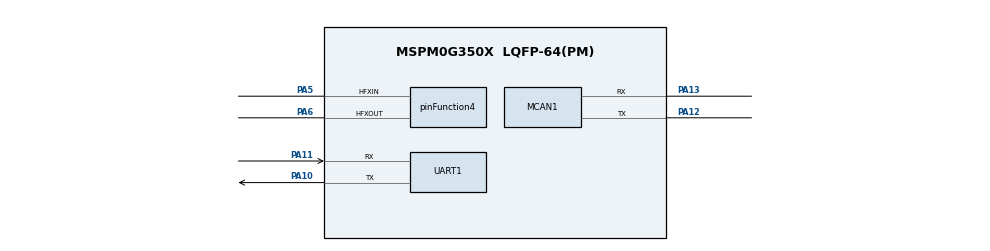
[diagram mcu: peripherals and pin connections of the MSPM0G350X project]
/**
 * @cliArgs --device "MSPM0G350X" --part "Default" --package "LQFP-64(PM)" --product "mspm0_sdk@2.10.00.04"
 * @versions {"tool":"1.27.0+4565"}
 */

/**
 * Import the modules used in this configuration.
 */
const MCAN   = scripting.addModule("/ti/driverlib/MCAN", {}, false);
const MCAN1  = MCAN.addInstance();
const SYSCTL = scripting.addModule("/ti/driverlib/SYSCTL");
const UART   = scripting.addModule("/ti/driverlib/UART", {}, false);
const UART1  = UART.addInstance();

/**
 * Write custom configuration values to the imported modules.
 */
const mux4       = system.clockTree["EXHFMUX"];
mux4.inputSelect = "EXHFMUX_XTAL";

const pinFunction4                        = system.clockTree["HFXT"];
pinFunction4.enable                       = true;
pinFunction4.inputFreq                    = 40;
pinFunction4.HFXTStartup                  = 10;
pinFunction4.HFCLKMonitor                 = true;
pinFunction4.peripheral.$assign           = "SYSCTL";
pinFunction4.peripheral.hfxInPin.$assign  = "PA5";
pinFunction4.peripheral.hfxOutPin.$assign = "PA6";

MCAN1.$name                    = "MCAN0";
MCAN1.enableInterrupt          = true;
MCAN1.autoWkupEnable           = true;
MCAN1.wkupReqEnable            = true;
MCAN1.emulationEnable          = true;
MCAN1.tdcEnable                = true;
MCAN1.additionalCoreConfig     = true;
MCAN1.rrfs                     = true;
MCAN1.rrfe                     = true;
MCAN1.interruptLine            = ["DL_MCAN_INTR_LINE_NUM_1"];
MCAN1.desiredNomRate           = 1000;
MCAN1.rxFIFO0ElemSize          = "DL_MCAN_ELEM_SIZE_8BYTES";
MCAN1.rxFIFO1ElemSize          = "DL_MCAN_ELEM_SIZE_8BYTES";
MCAN1.rxBufElemSize            = "DL_MCAN_ELEM_SIZE_8BYTES";
MCAN1.rxFIFO0waterMark         = 0;
MCAN1.m0interrupts             = ["DL_MCAN_MSP_INTERRUPT_LINE1"];
MCAN1.txBufNum                 = 1;
MCAN1.desiredDataRate          = 2;
MCAN1.stdFiltElem              = "001";
MCAN1.stdFiltType              = "00";
MCAN1.stdFiltID2               = 2047;
MCAN1.rxFIFO1size              = 0;
MCAN1.anfe                     = "2";
MCAN1.anfs                     = "2";
MCAN1.fdMode                   = false;
MCAN1.txStartAddr              = 8;
MCAN1.txBufElemSize            = "DL_MCAN_ELEM_SIZE_8BYTES";
MCAN1.txEventFIFOSize          = 0;
MCAN1.rxFIFO1waterMark         = 0;
MCAN1.interruptFlags           = ["DL_MCAN_INTERRUPT_RF0N"];
MCAN1.interruptLine1Flag       = ["DL_MCAN_INTERRUPT_RF0N"];
MCAN1.peripheral.$assign       = "CANFD0";
MCAN1.peripheral.rxPin.$assign = "PA13";
MCAN1.peripheral.txPin.$assign = "PA12";
MCAN1.txPinConfig.$name        = "ti_driverlib_gpio_GPIOPinGeneric2";
MCAN1.rxPinConfig.$name        = "ti_driverlib_gpio_GPIOPinGeneric3";

const Board = scripting.addModule("/ti/driverlib/Board", {}, false);

SYSCTL.forceDefaultClkConfig = true;
SYSCTL.clockTreeEn           = true;

UART1.$name                    = "UART_0";
UART1.targetBaudRate           = 115200;
UART1.enableFIFO               = true;
UART1.peripheral.$assign       = "UART0";
UART1.peripheral.rxPin.$assign = "PA11";
UART1.peripheral.txPin.$assign = "PA10";
UART1.txPinConfig.$name        = "ti_driverlib_gpio_GPIOPinGeneric0";
UART1.rxPinConfig.$name        = "ti_driverlib_gpio_GPIOPinGeneric1";

/**
 * Pinmux solution for unlocked pins/peripherals. This ensures that minor changes to the automatic solver in a future
 * version of the tool will not impact the pinmux you originally saw.  These lines can be completely deleted in order to
 * re-solve from scratch.
 */
Board.peripheral.$suggestSolution          = "DEBUGSS";
Board.peripheral.swclkPin.$suggestSolution = "PA20";
Board.peripheral.swdioPin.$suggestSolution = "PA19";
